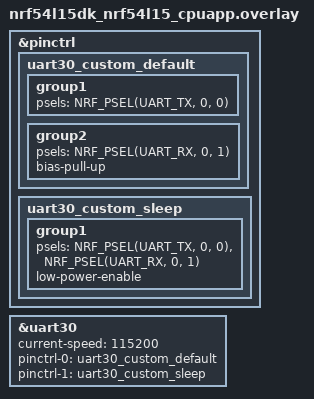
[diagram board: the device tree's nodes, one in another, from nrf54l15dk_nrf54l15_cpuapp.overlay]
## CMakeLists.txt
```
#
# Copyright (c) 2019 Nordic Semiconductor ASA
#
# SPDX-License-Identifier: LicenseRef-Nordic-5-Clause
#
cmake_minimum_required(VERSION 3.20.0)

find_package(Zephyr REQUIRED HINTS $ENV{ZEPHYR_BASE})
project(mesh_shell)

include_directories(${ZEPHYR_NRF_MODULE_DIR}/samples/bluetooth/mesh/common)

# NORDIC SDK APP START
target_sources(app PRIVATE
  src/main.c
  src/model_handler.c
  src/uart_cmd.c
  src/provisioning.c
  src/init.c
  src/gtw_shell.c
  src/keyrefresh.c
)
target_include_directories(app PRIVATE
  include
  ${ZEPHYR_NRF_MODULE_DIR}/samples/bluetooth/mesh/common
)

# Preinitialization related to DFU over SMP
target_sources_ifdef(CONFIG_MCUMGR_TRANSPORT_BT app PRIVATE
  ${ZEPHYR_NRF_MODULE_DIR}/samples/bluetooth/mesh/common/smp_bt.c
)

# NORDIC SDK APP END
```

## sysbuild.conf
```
#
# Copyright (c) 2020 Nordic Semiconductor ASA
#
# SPDX-License-Identifier: LicenseRef-Nordic-5-Clause
#
# Sysbuild configuration
# TFM UART configuration is passed via tfm_EXTRA_CONF_FILE or tfm image config
```

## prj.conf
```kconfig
#
# Copyright (c) 2020 Nordic Semiconductor ASA
#
# SPDX-License-Identifier: LicenseRef-Nordic-5-Clause
#

CONFIG_TEST=y
CONFIG_TEST_LOGGING_DEFAULTS=n
#CONFIG_INIT_STACKS=y
CONFIG_MAIN_STACK_SIZE=4096
CONFIG_ISR_STACK_SIZE=2048
CONFIG_SYSTEM_WORKQUEUE_STACK_SIZE=8192
CONFIG_SHELL_STACK_SIZE=4096

CONFIG_SHELL=y
CONFIG_SHELL_CMD_BUFF_SIZE=256
# CONFIG_SHELL_BACKEND_SERIAL=y
# CONFIG_SHELL_BACKEND_SERIAL_API_ASYNC=n
# CONFIG_SHELL_BACKEND_SERIAL_API_INTERRUPT_DRIVEN=y
CONFIG_UART_INTERRUPT_DRIVEN=y


# Dummy backend to capture shell output
CONFIG_SHELL_BACKEND_DUMMY=y
CONFIG_SHELL_BACKEND_DUMMY_BUF_SIZE=4096

# Use RTT for logging and shell
CONFIG_USE_SEGGER_RTT=y
CONFIG_RTT_CONSOLE=y
CONFIG_UART_CONSOLE=n
CONFIG_SHELL_BACKEND_SERIAL=n
CONFIG_SHELL_BACKEND_RTT=y
CONFIG_LOG_BACKEND_RTT=y
CONFIG_LOG_BACKEND_UART=n
# Use different RTT channels for shell and log
CONFIG_SHELL_BACKEND_RTT_BUFFER=0
CONFIG_LOG_BACKEND_RTT_BUFFER=1

CONFIG_BT_SETTINGS=y
CONFIG_FLASH=y
CONFIG_FLASH_MAP=y
CONFIG_SETTINGS=y
# CONFIG_SECURE_STORAGE=y

CONFIG_BT=y
CONFIG_BT_OBSERVER=y
CONFIG_BT_PERIPHERAL=y
CONFIG_BT_DEVICE_NAME="Zephyr Mesh"
CONFIG_BT_GATT_CACHING=n

CONFIG_BT_CTLR_LE_ENC=n
CONFIG_BT_CTLR_LE_PING=n
CONFIG_BT_DATA_LEN_UPDATE=n
CONFIG_BT_PHY_UPDATE=n
CONFIG_BT_CTLR_MIN_USED_CHAN=n
CONFIG_BT_CTLR_PRIVACY=n
CONFIG_BT_CTLR_DTM_HCI=n
CONFIG_BT_CTLR_EXT_SCAN_FP=n
CONFIG_BT_DATA_LEN_UPDATE=n
CONFIG_BT_CTLR_PER_INIT_FEAT_XCHG=n
#CONFIG_BT_CTLR_ADVANCED_FEATURES=y
CONFIG_BT_CTLR_FILTER_ACCEPT_LIST=n

CONFIG_BT_L2CAP_TX_BUF_COUNT=4


CONFIG_BT_RX_STACK_SIZE=4096

CONFIG_BT_MESH=y
CONFIG_BT_MESH_SHELL=y
CONFIG_BT_MESH_SHELL_HEALTH_SRV_INSTANCE=y
CONFIG_BT_MESH_SHELL_PROV_CTX_INSTANCE=y
CONFIG_BT_MESH_RELAY=y
CONFIG_BT_MESH_LOW_POWER=n
CONFIG_BT_MESH_LPN_AUTO=n
CONFIG_BT_MESH_FRIEND=y
CONFIG_BT_MESH_FRIEND_QUEUE_SIZE=16
CONFIG_BT_MESH_ADV_BUF_COUNT=9

CONFIG_BT_MESH_ADV_STACK_SIZE=4096
CONFIG_BT_MESH_CFG_CLI=y
CONFIG_BT_MESH_CFG_CLI_TIMEOUT=6000
CONFIG_BT_MESH_HEALTH_CLI=y
CONFIG_BT_MESH_TX_SEG_MSG_COUNT=2
CONFIG_BT_MESH_RX_SEG_MSG_COUNT=2
CONFIG_BT_MESH_RX_SEG_MAX=32
CONFIG_BT_MESH_TX_SEG_MAX=32
CONFIG_BT_MESH_CRPL=128

CONFIG_BT_MESH_PB_GATT=y
CONFIG_BT_MESH_PB_ADV=y
CONFIG_BT_MESH_GATT_PROXY=y
CONFIG_BT_MESH_NODE_ID_TIMEOUT=10

# The gateway must be a member of every subnet it provisions devices onto (to
# configure and drive those nodes), so it needs more than the default of 1
# subnet. Capped below CDB_SUBNET_COUNT by RAM; prov_ensure_subnet reports a
# clean error if a provisioning would exceed this.
CONFIG_BT_MESH_SUBNET_COUNT=10
CONFIG_BT_MESH_APP_KEY_COUNT=20
# PTS requires more key slots when using Opcodes Aggregator.
# First one is implicitly taken by Device Key.
CONFIG_BT_MESH_MODEL_KEY_COUNT=10
CONFIG_BT_MESH_MODEL_GROUP_COUNT=2
CONFIG_BT_MESH_LABEL_COUNT=1

CONFIG_LOG=y
CONFIG_LOG_BUFFER_SIZE=4096
CONFIG_LOG_PROCESS_THREAD_SLEEP_MS=100
CONFIG_LOG_MODE_DEFERRED=y

CONFIG_BT_MESH_IV_UPDATE_TEST=y
# INF (not DBG): verbose mesh debug logging floods deferred RTT logging during
# heavy mesh traffic, adding CPU/timing pressure that can push HCI commands past
# their timeout. INF keeps useful info logs without the per-PDU debug spam.
CONFIG_BT_MESH_LOG_LEVEL_INF=y
CONFIG_BT_MESH_CDB=y
CONFIG_BT_MESH_CDB_SUBNET_COUNT=10
CONFIG_BT_MESH_CDB_APP_KEY_COUNT=15
CONFIG_BT_MESH_CDB_NODE_COUNT=128
CONFIG_BT_MESH_PROVISIONER=y

#Added includes
CONFIG_DK_LIBRARY=y
CONFIG_BT_MESH_ONOFF_SRV=y
CONFIG_BT_MESH_ONOFF_CLI=y
CONFIG_BT_MESH_LIGHTNESS_CLI=y
CONFIG_BT_MESH_SCENE_CLI=y
CONFIG_BT_MESH_SENSOR_CLI=y
CONFIG_BT_MESH_RPR_CLI=y
CONFIG_BT_MESH_SHELL_RPR_CLI=n

# CONFIG_TFM_ITS_NUM_ASSETS_OVERRIDE=y
# CONFIG_TFM_ITS_NUM_ASSETS=50
# CONFIG_PM_PARTITION_SIZE_TFM_INTERNAL_TRUSTED_STORAGE=0x8000

CONFIG_MBEDTLS_HEAP_SIZE=16384
CONFIG_MBEDTLS_PSA_KEY_SLOT_COUNT=64

# UART30 for board-to-board command reception (see board overlay)
CONFIG_SERIAL=y
CONFIG_UART_30_INTERRUPT_DRIVEN=y
CONFIG_BT_MESH_CDB_KEY_SYNC=y

CONFIG_NRF_PLATFORM_LUMOS=n
```

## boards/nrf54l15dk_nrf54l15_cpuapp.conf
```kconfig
#
# Copyright (c) 2024 Nordic Semiconductor ASA
#
# SPDX-License-Identifier: LicenseRef-Nordic-5-Clause
#
# nRF54L15 uses ZMS (RRAM), not NVS. Required for mesh trusted storage backend.

CONFIG_NVS=n
CONFIG_NVS_LOOKUP_CACHE=n
CONFIG_SETTINGS_NVS_NAME_CACHE=n
CONFIG_ZMS=y
CONFIG_SETTINGS_ZMS_CUSTOM_SECTOR_COUNT=y
CONFIG_SETTINGS_ZMS_SECTOR_COUNT=8
CONFIG_ZMS_LOOKUP_CACHE=y
CONFIG_ZMS_LOOKUP_CACHE_SIZE=512
CONFIG_ZMS_LOOKUP_CACHE_FOR_SETTINGS=y
```

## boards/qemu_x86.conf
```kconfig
# Copyright (c) 2026 Nordic Semiconductor ASA
# SPDX-License-Identifier: LicenseRef-Nordic-5-Clause

# nrf_security only supports Cortex-M via PSA crypto libraries.
# Enforcing usage of built-in Mbed TLS for native simulator.
CONFIG_NRF_SECURITY=n
CONFIG_MBEDTLS_ENABLE_HEAP=n
CONFIG_TRUSTED_STORAGE=n
CONFIG_SECURE_STORAGE=y
```

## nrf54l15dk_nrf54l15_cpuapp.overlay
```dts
/*
 * Copyright (c) 2026 Nordic Semiconductor ASA
 *
 * SPDX-License-Identifier: LicenseRef-Nordic-5-Clause
 */

/*
 * UART30 overlay for board-to-board command communication with nRF9151 gateway.
 * Console uses RTT in this application; UART20 is unused.
 * Hardware flow control (RTS/CTS) disabled for simple 2-wire UART.
 */

&pinctrl {
	uart30_custom_default: uart30_custom_default {
		group1 {
			psels = <NRF_PSEL(UART_TX, 0, 0)>;
		};
		group2 {
			psels = <NRF_PSEL(UART_RX, 0, 1)>;
			bias-pull-up;
		};
	};

	uart30_custom_sleep: uart30_custom_sleep {
		group1 {
			psels = <NRF_PSEL(UART_TX, 0, 0)>,
				<NRF_PSEL(UART_RX, 0, 1)>;
			low-power-enable;
		};
	};
};

&uart30 {
	status = "okay";
	current-speed = <115200>;
	pinctrl-0 = <&uart30_custom_default>;
	pinctrl-1 = <&uart30_custom_sleep>;
	pinctrl-names = "default", "sleep";
};
```

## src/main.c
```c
/*
 * Copyright (c) 2017 Intel Corporation
 * Copyright (c) 2026 Nordic Semiconductor ASA
 *
 * SPDX-License-Identifier: Apache-2.0
 */

#include <zephyr/sys/printk.h>
#include <zephyr/console/console.h>
#include <zephyr/kernel.h>
#include <zephyr/bluetooth/bluetooth.h>
#include <bluetooth/mesh/models.h>
#include <bluetooth/mesh/dk_prov.h>
#include <dk_buttons_and_leds.h>
#include <zephyr/shell/shell.h>
#include <zephyr/shell/shell_uart.h>
#include <zephyr/shell/shell_dummy.h>
#include <zephyr/bluetooth/mesh/shell.h>
#include "model_handler.h"
#include "init.h"
#include "uart_cmd.h"
#include "smp_bt.h"
#include "provisioning.h"

/*ADDED INCLUDES*/
#include <zephyr/settings/settings.h>
#include <zephyr/drivers/uart.h>
#include <zephyr/logging/log_backend.h>
#include <zephyr/logging/log_output.h>
#include <zephyr/logging/log_ctrl.h>
#include <zephyr/sys/ring_buffer.h>
#include <string.h>
#include <stdio.h>

#if defined(CONFIG_SETTINGS)
#include <zephyr/settings/settings.h>
#endif



int main(void)
{
	int err;

	printk("Initializing...\n");
	err = bt_enable(bt_ready);
	if (err && err != -EALREADY) {
		printk("Bluetooth init failed (err %d)\n", err);
	}
	err = uart_cmd_init();
	if (err) {
		printk("UART command init failed (err %d)\n", err);
	}
	provisioning_init();
	printk("Press the <Tab> button for supported commands.\n");
	printk("Before any Mesh commands you must run \"mesh init\"\n");
	printk("Ready to receive commands via UART...\n");
	while (1) {
		k_sleep(K_FOREVER);
	}
	return 0;
}
```

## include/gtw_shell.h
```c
/*
 * Copyright (c) 2026 Nordic Semiconductor ASA
 *
 * SPDX-License-Identifier: LicenseRef-Nordic-5-Clause
 */

#ifndef GTW_SHELL_H
#define GTW_SHELL_H

#define STATUS_GROUP_ADDR 0xC000

bool queue_shell_cmd(const char *cmd);

#endif /* GTW_SHELL_H */
```

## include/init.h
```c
/*
 * Copyright (c) 2019 Nordic Semiconductor ASA
 *
 * SPDX-License-Identifier: LicenseRef-Nordic-5-Clause
 */

/**
 * @file
 * @brief Model handler
 */

#ifndef INIT_H
#define INIT_H

#include <zephyr/drivers/uart.h>
#include <zephyr/bluetooth/bluetooth.h>

#ifdef __cplusplus
extern "C" {
#endif

int uart_cmd_init(void);
void bt_ready(int err);


#ifdef __cplusplus
}
#endif

#endif /* INIT_H__ */
```

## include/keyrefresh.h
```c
/*
 * Copyright (c) 2026 Nordic Semiconductor ASA
 *
 * SPDX-License-Identifier: LicenseRef-Nordic-5-Clause
 */

#ifndef KEYREFRESH_H
#define KEYREFRESH_H

#include <stddef.h>
#include <stdint.h>

#ifdef __cplusplus
extern "C" {
#endif

/* One subnet to refresh and the remote nodes that hold it. The gateway is
 * always refreshed too, so it is not listed.
 */
struct kr_subnet {
	uint16_t net_idx;
	const uint16_t *addrs;
	size_t addr_count;
};

/* Run the Bluetooth Mesh Key Refresh on the selected
 * NetKeys and AppKeys
 */
void key_refresh_run(const struct kr_subnet *subnets, size_t subnet_count,
		     const uint16_t *app_idxs, size_t app_count,
		     uint16_t evict_addr);

#ifdef __cplusplus
}
#endif

#endif /* KEYREFRESH_H */
```

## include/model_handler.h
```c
/*
 * Copyright (c) 2026 Nordic Semiconductor ASA
 *
 * SPDX-License-Identifier: LicenseRef-Nordic-5-Clause
 */

/**
 * @file
 * @brief Model handler
 */

#ifndef MODEL_HANDLER_H__
#define MODEL_HANDLER_H__

#include <stdbool.h>
#include <stdint.h>
#include <zephyr/bluetooth/mesh.h>

#ifdef __cplusplus
extern "C" {
#endif

const struct bt_mesh_comp *model_handler_init(void);
int model_handler_onoff_set(uint16_t net_idx, uint16_t app_idx, uint16_t dst_addr, bool on_off);

/* Set absolute brightness (0-100%) on a Light Lightness Server (light_ctrl fixture). */
int model_handler_lightness_set(uint16_t net_idx, uint16_t app_idx, uint16_t dst_addr,
				uint8_t percent);

/* Recall/store a scene on a Scene Server. */
int model_handler_scene_recall(uint16_t net_idx, uint16_t app_idx, uint16_t dst_addr,
			       uint16_t scene);
int model_handler_scene_store(uint16_t net_idx, uint16_t app_idx, uint16_t dst_addr,
			      uint16_t scene);

/* Read bt_mesh_sensor_precise_tot_dev_energy_use
 */
int model_handler_sensor_get(uint16_t net_idx, uint16_t app_idx, uint16_t dst_addr);

#if defined(CONFIG_BT_MESH_RPR_CLI)
/* Remote Provisioning Client model instance */
struct bt_mesh_rpr_cli *model_handler_rpr_cli(void);
#endif

#ifdef __cplusplus
}
#endif

#endif /* MODEL_HANDLER_H__ */
```

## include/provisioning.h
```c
/*
 * Copyright (c) 2026 Nordic Semiconductor ASA
 *
 * SPDX-License-Identifier: LicenseRef-Nordic-5-Clause
 */

#ifndef PROVISIONING_H
#define PROVISIONING_H

#include <stdbool.h>
#include <stdint.h>

#ifdef __cplusplus
extern "C" {
#endif

/* Control/status group the gateway subscribes its own client models to, and the
 * group fixtures publish their status to, so the cloud sees state changes from any
 * source. Shared by the local-model setup in uart_cmd.c and the remote-node
 * auto-configuration here.
 */
#define STATUS_GROUP_ADDR 0xC000

/* One-time provisioning subsystem setup */
void provisioning_init(void);

/* Ensure subnet `net_idx` exists in the CDB and is added to the gateway's own
 * node
 */
int prov_ensure_subnet(uint16_t net_idx, const char *netkey_hex);

/* Add subnet to an already-provisioned node
 */
int prov_node_add_subnet(uint16_t net_idx, uint16_t addr, uint16_t add_net_idx);

/* Remove subnet from a node */
int prov_node_del_subnet(uint16_t net_idx, uint16_t addr, uint16_t del_net_idx);

/* Remove one AppKey from a node */
int prov_node_del_appkey(uint16_t net_idx, uint16_t addr, uint16_t app_idx);

/* Remove a group address from a node: unsubscribe its models from the group and
 * clear any publication aimed at it.
 */
int prov_node_del_group(uint16_t net_idx, uint16_t addr, uint16_t group);

/* Toggle combined scanning: local unprovisioned beacons + remote RPR relays. */
void prov_scan_toggle(void);

/* Toggle REMOTE-ONLY scanning: RPR relays only, local beacons stay off. */
void prov_scan_rpr_toggle(void);

/* Enable/disable auto-provisioning of newly discovered unprovisioned devices. */
void prov_auto_set(bool enable);

/* net_idx/app_idx/group to use for provisioning. */
extern uint16_t cur_net_idx;
extern uint16_t cur_app_idx;
extern uint16_t cur_group;

/* Provision a discovered device (by UUID). Tunnels through the discovering RPR
 * relay if the UUID was seen remotely, otherwise provisions locally over PB-ADV.
 */
void prov_provision(const char *uuid);

/* Register a node address as a known RPR Server relay (dedup-insert). */
void prov_rpr_server_add(uint16_t addr);

/* Report the registered RPR Server relays to the cloud. */
void prov_rpr_server_list(void);

/* Read a freshly provisioned node's composition data and queue configuration
 * commands for the models the gateway recognizes.
 */
void configure_and_report(uint16_t addr, uint16_t net_idx, uint16_t app_idx,
			      uint16_t group);

#ifdef __cplusplus
}
#endif

#endif /* PROVISIONING_H */
```

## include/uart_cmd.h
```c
/*
 * Copyright (c) 2026 Nordic Semiconductor ASA
 *
 * SPDX-License-Identifier: LicenseRef-Nordic-5-Clause
 */

#ifndef UART_CMD_H
#define UART_CMD_H

#include <zephyr/drivers/uart.h>
#include <zephyr/kernel.h>

#ifdef __cplusplus
extern "C" {
#endif

void uart30_send(const char *data, const char *subject);


#ifdef __cplusplus
}
#endif

#endif /* UART_CMD_H */
```

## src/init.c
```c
/*
 * Copyright (c) 2026 Nordic Semiconductor ASA
 *
 * SPDX-License-Identifier: LicenseRef-Nordic-5-Clause
 */

/*UART INIT*/
#include "init.h"
#include <zephyr/drivers/uart.h>
#include <zephyr/bluetooth/mesh/shell.h>
#include <zephyr/bluetooth/bluetooth.h>
#include <zephyr/settings/settings.h>
#include <zephyr/sys/printk.h>
#include "model_handler.h"

void bt_ready(int err)
{
	if (err && err != -EALREADY) {
		printk("Bluetooth init failed (err %d)\n", err);
		return;
	}
	printk("Bluetooth initialized\n");
	int mesh_err = bt_mesh_init(&bt_mesh_shell_prov, model_handler_init());

	if (mesh_err) {
		printk("Initializing mesh failed (err %d)\n", mesh_err);
		return;
	}
	if (IS_ENABLED(CONFIG_SETTINGS)) {
		settings_load();
	}
	if (bt_mesh_is_provisioned()) {
		printk("Mesh network restored from flash\n");
	} else {
		printk("Use \"prov pb-adv on\" or \"prov pb-gatt on\" to enable advertising\n");
	}
}
```

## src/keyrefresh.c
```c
/*
 * Copyright (c) 2026 Nordic Semiconductor ASA
 *
 * SPDX-License-Identifier: LicenseRef-Nordic-5-Clause
 */

#include "keyrefresh.h"
#include "uart_cmd.h"   /* uart30_send */

#include <stdbool.h>
#include <stdint.h>
#include <stddef.h>
#include <stdio.h>

#include <zephyr/kernel.h>
#include <zephyr/sys/printk.h>
#include <zephyr/sys/util.h>

#include <zephyr/bluetooth/mesh.h>
#include <zephyr/bluetooth/mesh/cdb.h>
#include <zephyr/bluetooth/mesh/cfg_cli.h>
#include <zephyr/bluetooth/crypto.h>

/* bt_mesh_primary_addr() (the gateway's own primary unicast) */
uint16_t bt_mesh_primary_addr(void);

/* Bluetooth Mesh Key Refresh phase/transition values */
#define KR_PHASE_NORMAL   0x00
#define KR_PHASE_1	0x01
#define KR_PHASE_2	0x02
#define KR_TRANS_PHASE_2  0x02
#define KR_TRANS_PHASE_3  0x03

/* All provisioned nodes plus the local gateway (not stored in the CDB). */
#define KR_MAX_TARGETS    (CONFIG_BT_MESH_CDB_NODE_COUNT + 1)

/* Scratch buffer for the target list. Only ever touched by the single
 * serialized worker that runs key_refresh_run().
 */
static uint16_t kr_targets[KR_MAX_TARGETS];

/* Is app_idx one of the `count` selected AppKeys? */
static bool kr_app_selected(uint16_t app_idx, const uint16_t *sel, size_t count)
{
	for (size_t i = 0; i < count; i++) {
		if (sel[i] == app_idx) {
			return true;
		}
	}
	return false;
}

/* Runs the full three-phase Key Refresh for one subnet, rolling its NetKey and */
/* every selected AppKey (`sel`/`sel_count`) that is bound to this subnet. */
static void key_refresh_subnet(const struct kr_subnet *target,
				   const uint16_t *sel, size_t sel_count,
				   uint16_t evict_addr, bool del_evicted)
{
	uint16_t refresh_net_idx = target->net_idx;
	struct bt_mesh_cdb_subnet *sub = bt_mesh_cdb_subnet_get(refresh_net_idx);
	uint16_t local_addr = bt_mesh_primary_addr();
	uint8_t new_key[16];
	/* One fresh value per CDB AppKey slot (only meaningful where ak_done[] is */
	/* set), indexed by the slot's position in bt_mesh_cdb.app_keys[]. */
	uint8_t new_app_keys[ARRAY_SIZE(bt_mesh_cdb.app_keys)][16];
	bool ak_done[ARRAY_SIZE(bt_mesh_cdb.app_keys)] = { 0 };
	size_t ak_count = 0;
	char resp[192];
	size_t n;
	int p1_fail = 0, p2_fail = 0, p3_fail = 0, ak_fail = 0;

	/* All key_refresh_run failures report under the "KeyRefresh" subject (not */
	/* "Error") so the website — which set its status to "running" the moment the */
	/* command was dispatched — routes them to its key-refresh handler and clears */
	/* that pending state instead of leaving the badge stuck. */
	if (!sub) {
		snprintf(resp, sizeof(resp), "key refresh: no subnet 0x%03x in database",
			refresh_net_idx);
		printk("%s\n", resp);
		uart30_send(resp, "KeyRefresh");
		return;
	}
	if (sub->kr_phase != KR_PHASE_NORMAL) {
		snprintf(resp, sizeof(resp),
			"key refresh: subnet 0x%03x already refreshing (phase 0x%02x)",
			refresh_net_idx, sub->kr_phase);
		printk("%s\n", resp);
		uart30_send(resp, "KeyRefresh");
		return;
	}
	/* Evicting the gateway's own node would leave every remote on the new key */
	/* while the gateway keeps the old one, partitioning it from the network it */
	/* provisions. Never allow it. */
	if (evict_addr && evict_addr == local_addr) {
		snprintf(resp, sizeof(resp),
			"key refresh: refusing to evict gateway 0x%04x", local_addr);
		printk("%s\n", resp);
		uart30_send(resp, "KeyRefresh");
		return;
	}

	/* One fresh random NetKey shared by every node. The same value MUST reach */
	/* all nodes, so we generate it once here rather than letting each config */
	/* command mint its own (the shell would fall back to the default key). */
	if (bt_rand(new_key, sizeof(new_key))) {
		uart30_send("key refresh: RNG failed", "KeyRefresh");
		return;
	}

	/* Target list: the nodes the caller says hold this subnet (the gateway */
	/* does not track which subnets each node holds), then the local gateway, */
	/* which holds every subnet and goes last so it keeps the old key until */
	/* every remote has switched. */
	n = 0;
	for (size_t i = 0; i < target->addr_count && n < KR_MAX_TARGETS - 1; i++) {
		uint16_t addr = target->addrs[i];

		if (addr == evict_addr || addr == local_addr) {
			continue;
		}
		if (!bt_mesh_cdb_node_get(addr)) {
			printk("  0x%04x not in database, skipping\n", addr);
			continue;
		}
		kr_targets[n++] = addr;
	}
	if (local_addr) {
		kr_targets[n++] = local_addr;
	}
	if (n == 0) {
		uart30_send("key refresh: no target nodes", "KeyRefresh");
		return;
	}

	printk("Key refresh on subnet 0x%03x: %u node(s)%s\n", refresh_net_idx,
	   (unsigned int)n, evict_addr ? " (evicting one)" : "");
	snprintf(resp, sizeof(resp), "started subnet 0x%03x nodes=%u evict=0x%04x",
		 refresh_net_idx, (unsigned int)n, evict_addr);
	uart30_send(resp, "KeyRefresh");

	/* ---- Phase 1: distribute the new key (§3.11.4.1) ---- */
	/* Record the new key in the database as the "new" key (index 1) first, then */
	/* push it to each node. A NetKey Update moves a node from Normal to Phase 1; */
	/* it then keeps TX on the old key and RX on both keys. */
	bt_mesh_cdb_subnet_key_import(sub, 1, new_key);
	sub->kr_phase = KR_PHASE_1;
	bt_mesh_cdb_subnet_store(sub);

	for (size_t i = 0; i < n; i++) {
		uint8_t status = 0;
		int err = bt_mesh_cfg_cli_net_key_update(refresh_net_idx, kr_targets[i],
							refresh_net_idx, new_key, &status);
		if (err || status) {
			p1_fail++;
			printk("  P1 net-key-update 0x%04x FAILED (err %d, status 0x%02x)\n",
			kr_targets[i], err, status);
		}
	}

	/* The selected AppKeys on this subnet, refreshed while still in Phase 1. */
	for (size_t ak = 0; ak < ARRAY_SIZE(bt_mesh_cdb.app_keys); ak++) {
		struct bt_mesh_cdb_app_key *key = &bt_mesh_cdb.app_keys[ak];

		/* Only refresh selected AppKeys bound to this NetKey. */
		if (key->net_idx != refresh_net_idx ||
			!kr_app_selected(key->app_idx, sel, sel_count)) {
			continue;
		}
		if (bt_rand(new_app_keys[ak], sizeof(new_app_keys[ak]))) {
			printk("  AppKey 0x%04x: RNG failed, skipping\n", key->app_idx);
			continue;
		}

		bt_mesh_cdb_app_key_import(key, 1, new_app_keys[ak]);
		ak_done[ak] = true;
		ak_count++;

		for (size_t i = 0; i < n; i++) {
			uint8_t status = 0;
			int err = bt_mesh_cfg_cli_app_key_update(refresh_net_idx, kr_targets[i],
								refresh_net_idx, key->app_idx,
								new_app_keys[ak], &status);
			if (err) {
				ak_fail++;
				printk("  P1 app-key-update 0x%04x appidx=0x%04x FAILED (err %d)\n",
					kr_targets[i], key->app_idx, err);
			} else if (status) {
				printk(
			"  P1 app-key-update 0x%04x appidx=0x%04x not applicable (status 0x%02x)\n",
					kr_targets[i], key->app_idx, status);
			}
		}
	}

	/* ---- Phase 2: switch every node's TX to the new key (§3.11.4.2) ---- */
	for (size_t i = 0; i < n; i++) {
		uint8_t status = 0, phase = 0;
		int err = bt_mesh_cfg_cli_krp_set(refresh_net_idx, kr_targets[i],
						refresh_net_idx, KR_TRANS_PHASE_2,
						&status, &phase);
		if (err || status || phase != KR_PHASE_2) {
			p2_fail++;
			printk("  P2 krp-set 0x%04x FAILED (err %d, status 0x%02x, phase 0x%02x)\n",
				kr_targets[i], err, status, phase);
		}
	}
	sub->kr_phase = KR_PHASE_2;
	bt_mesh_cdb_subnet_store(sub);

	/* ---- Phase 3: revoke the old key (§3.11.4.3) ---- */
	/* Iterating in build order revokes the local gateway last, so it keeps a */
	/* working old key until every remote has switched. Each node settles back */
	/* to Normal (0x00) once the old key is revoked. */
	for (size_t i = 0; i < n; i++) {
		uint8_t status = 0, phase = 0;
		int err = bt_mesh_cfg_cli_krp_set(refresh_net_idx, kr_targets[i],
						refresh_net_idx, KR_TRANS_PHASE_3,
						&status, &phase);
		if (err || status || phase != KR_PHASE_NORMAL) {
			p3_fail++;
			printk("  P3 krp-set 0x%04x FAILED (err %d, status 0x%02x, phase 0x%02x)\n",
				kr_targets[i], err, status, phase);
		}
	}

	/* The new key is now the sole key on the network; mirror that in the CDB. */
	bt_mesh_cdb_subnet_key_import(sub, 0, new_key);
	sub->kr_phase = KR_PHASE_NORMAL;
	bt_mesh_cdb_subnet_store(sub);

	/* Same promotion for every AppKey that was refreshed above. */
	for (size_t ak = 0; ak < ARRAY_SIZE(bt_mesh_cdb.app_keys); ak++) {
		if (!ak_done[ak]) {
			continue;
		}
		struct bt_mesh_cdb_app_key *key = &bt_mesh_cdb.app_keys[ak];

		bt_mesh_cdb_app_key_import(key, 0, new_app_keys[ak]);
		bt_mesh_cdb_app_key_store(key);
	}

	/* An evicted node never received the new key and is now off the network, so */
	/* drop it from the database as well. Skipped when several subnets are */
	/* refreshed: key_refresh_run removes the node once, after the last subnet. */
	if (del_evicted && evict_addr) {
		struct bt_mesh_cdb_node *gone = bt_mesh_cdb_node_get(evict_addr);

		if (gone) {
			bt_mesh_cdb_node_del(gone, true);
			printk("Evicted node 0x%04x removed from database\n", evict_addr);
		}
	}

	snprintf(resp, sizeof(resp),
		 "complete subnet 0x%03x nodes=%u appkeys=%u fails p1=%d p2=%d p3=%d ak=%d%s",
		 refresh_net_idx, (unsigned int)n, (unsigned int)ak_count,
		 p1_fail, p2_fail, p3_fail, ak_fail,
		 evict_addr ? " evicted" : "");
	printk("Key refresh %s\n", resp);
	uart30_send(resp, "KeyRefresh");
}

/* Refresh the selected subnets' NetKeys (`subnets`/`subnet_count`), each across
 * the nodes listed with it, optionally rolling the selected AppKeys
 * (`app_idxs`/`app_count`) alongside their own subnet's NetKey.
 */
void key_refresh_run(const struct kr_subnet *subnets, size_t subnet_count,
		     const uint16_t *app_idxs, size_t app_count,
		     uint16_t evict_addr)
{
	char resp[96];

	if (subnet_count == 0) {
		uart30_send("key refresh: no subnet selected", "KeyRefresh");
		return;
	}

	/* An AppKey is only rolled with its own subnet, whose node list must be */
	/* in the command - flag any whose subnet was not selected. */
	for (size_t i = 0; i < app_count; i++) {
		struct bt_mesh_cdb_app_key *key = bt_mesh_cdb_app_key_get(app_idxs[i]);
		bool selected = false;

		if (!key) {
			snprintf(resp, sizeof(resp),
				"key refresh: app_idx 0x%03x not in database", app_idxs[i]);
			printk("%s\n", resp);
			uart30_send(resp, "KeyRefresh");
			continue;
		}
		for (size_t j = 0; j < subnet_count; j++) {
			if (subnets[j].net_idx == key->net_idx) {
				selected = true;
				break;
			}
		}
		if (!selected) {
			snprintf(resp, sizeof(resp),
				"key refresh: app_idx 0x%03x skipped, its subnet 0x%03x not selected",
				app_idxs[i], key->net_idx);
			printk("%s\n", resp);
			uart30_send(resp, "KeyRefresh");
		}
	}

	/* Refresh each subnet once, passing the full AppKey selection; the subnet
	 * routine rolls its NetKey plus the selected AppKeys bound to it.
	 * Defer the evicted-node removal to after the last subnet.
	 */
	for (size_t j = 0; j < subnet_count; j++) {
		key_refresh_subnet(&subnets[j], app_idxs, app_count, evict_addr,
				/* del_evicted = */ false);
	}

	/* Each subnet refused to evict the gateway itself (it must stay on the new */
	/* key), so never drop the local node here either - only a genuine remote. */
	if (evict_addr && evict_addr != bt_mesh_primary_addr()) {
		struct bt_mesh_cdb_node *gone = bt_mesh_cdb_node_get(evict_addr);

		if (gone) {
			bt_mesh_cdb_node_del(gone, true);
			printk("Evicted node 0x%04x removed from database\n", evict_addr);
		}
	}
}
```

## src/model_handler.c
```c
/*
 * Copyright (c) 2026 Nordic Semiconductor ASA
 *
 * SPDX-License-Identifier: LicenseRef-Nordic-5-Clause
 */

#include <zephyr/bluetooth/bluetooth.h>
#include <bluetooth/mesh/models.h>
#include <bluetooth/mesh/gen_onoff_cli.h>
#include <errno.h>
#include <stdio.h>
#include <zephyr/sys/printk.h>
#include "uart_cmd.h"

/*ADDED INCLUDES*/
#include <zephyr/shell/shell.h>
#include <zephyr/bluetooth/mesh/shell.h>

static struct bt_mesh_cfg_cli cfg_cli;

#if defined(CONFIG_BT_MESH_RPR_CLI)
/* Remote Provisioning Client instance */
static struct bt_mesh_rpr_cli rpr_cli;

struct bt_mesh_rpr_cli *model_handler_rpr_cli(void)
{
	return &rpr_cli;
}
#endif

/* callback for receiving on/off status messages from the mesh network, sends status to cloud */
static void OnOff_status_cb(struct bt_mesh_onoff_cli *cli,
			    struct bt_mesh_msg_ctx *ctx,
			    const struct bt_mesh_onoff_status *status)
{
	(void)cli;

	if (!ctx || !status) {
		printk("OnOff status callback received invalid data\n");
		return;
	}

	printk("OnOff status from 0x%04x: status=%u",
	       ctx->addr,
	       status->present_on_off ? 1U : 0U);

	if (status->remaining_time >= 0) {
		printk(", target=%u, remaining=%ld ms",
		       status->target_on_off ? 1U : 0U,
		       (long)status->remaining_time);
	}

	printk("\n");

	char status_msg[96];

	snprintf(status_msg, sizeof(status_msg),
		 "src=0x%04x status=%s",
		 ctx->addr,
		 status->present_on_off ? "ON" : "OFF");
	uart30_send(status_msg, "OnOff_status");
}

static struct bt_mesh_onoff_cli onoff_cli = BT_MESH_ONOFF_CLI_INIT(OnOff_status_cb);

/* callback for Light Lightness status, forwards the brightness level to the cloud */
static void lightness_status_cb(struct bt_mesh_lightness_cli *cli,
				struct bt_mesh_msg_ctx *ctx,
				const struct bt_mesh_lightness_status *status)
{
	(void)cli;

	if (!ctx || !status) {
		return;
	}

	printk("Lightness status from 0x%04x: lvl=%u\n", ctx->addr, status->current);

	char msg[96];

	snprintf(msg, sizeof(msg), "src=0x%04x lvl=%u", ctx->addr, status->current);
	/* Subject must be <=15 chars: the nRF9151 forwarder parses the appId with
	 * sscanf("%15s") into a 16-byte buffer, so "Lightness_status" (16) would be
	 * truncated to "Lightness_statu" and never match on the cloud side.
	 */
	uart30_send(msg, "Light_status");
}

static const struct bt_mesh_lightness_cli_handlers lightness_cli_handlers = {
	.light_status = lightness_status_cb,
};

/* Light Lightness client, used by the gateway to set absolute brightness on fixtures */
static struct bt_mesh_lightness_cli lightness_cli =
	BT_MESH_LIGHTNESS_CLI_INIT(&lightness_cli_handlers);

/* callback for Scene status, forwards the current scene to the cloud */
static void scene_status_cb(struct bt_mesh_scene_cli *cli,
			    struct bt_mesh_msg_ctx *ctx,
			    const struct bt_mesh_scene_state *state)
{
	(void)cli;

	if (!ctx || !state) {
		return;
	}

	printk("Scene status from 0x%04x: current=%u\n", ctx->addr, state->current);

	char msg[96];

	snprintf(msg, sizeof(msg), "src=0x%04x scene=%u", ctx->addr, state->current);
	uart30_send(msg, "Scene_status");
}

/* Scene client, used by the gateway to store/recall scenes on fixtures */
static struct bt_mesh_scene_cli scene_cli = {
	.status = scene_status_cb,
};

/* callback for Sensor Status: decode the Precise Total Device Energy Use value
 * and forward it to the cloud. The Sensor Client already decodes the on-air
 * wire format into a bt_mesh_sensor_value; we convert that to a number using
 * the property's format (energy32: unit kWh, resolution 0.001 kWh).
 */
static void sensor_data_cb(struct bt_mesh_sensor_cli *cli,
			   struct bt_mesh_msg_ctx *ctx,
			   const struct bt_mesh_sensor_type *sensor,
			   const struct bt_mesh_sensor_value *value)
{
	(void)cli;

	if (!ctx || !sensor || !value) {
		return;
	}

	/* The gateway only queries the energy-use sensor; ignore anything else */
	if (sensor->id != BT_MESH_PROP_ID_PRECISE_TOT_DEV_ENERGY_USE) {
		printk("Sensor status from 0x%04x: unhandled property 0x%04x\n",
		       ctx->addr, sensor->id);
		return;
	}

	int64_t micro_kwh = 0;
	enum bt_mesh_sensor_value_status st =
		bt_mesh_sensor_value_to_micro(&value[0], &micro_kwh);
	char msg[64];

	if (!bt_mesh_sensor_value_status_is_numeric(st)) {
		printk("Energy status from 0x%04x: non-numeric value (status %d)\n",
		       ctx->addr, (int)st);
		snprintf(msg, sizeof(msg), "src=0x%04x ukwh=unknown", ctx->addr);
		uart30_send(msg, "Energy_status");
		return;
	}
	printk("Energy status from 0x%04x: %lld micro-kWh\n", ctx->addr, micro_kwh);

	snprintf(msg, sizeof(msg), "src=0x%04x ukwh=%lld", ctx->addr, micro_kwh);

	uart30_send(msg, "Energy_status");
}

static const struct bt_mesh_sensor_cli_handlers sensor_cli_handlers = {
	.data = sensor_data_cb,
};

static struct bt_mesh_sensor_cli sensor_cli =
	BT_MESH_SENSOR_CLI_INIT(&sensor_cli_handlers);

#if defined(CONFIG_BT_MESH_DFD_SRV)
static struct bt_mesh_dfd_srv dfd_srv;
#endif

#if defined(CONFIG_BT_MESH_SAR_CFG_CLI)
static struct bt_mesh_sar_cfg_cli sar_cfg_cli;
#endif

#if defined(CONFIG_BT_MESH_PRIV_BEACON_CLI)
static struct bt_mesh_priv_beacon_cli priv_beacon_cli;
#endif

#if defined(CONFIG_BT_MESH_SOL_PDU_RPL_CLI)
static struct bt_mesh_sol_pdu_rpl_cli srpl_cli;
#endif


#if defined(CONFIG_BT_MESH_OD_PRIV_PROXY_CLI)
static struct bt_mesh_od_priv_proxy_cli od_priv_proxy_cli;
#endif

#if defined(CONFIG_BT_MESH_LARGE_COMP_DATA_CLI)
struct bt_mesh_large_comp_data_cli large_comp_data_cli;
#endif

#if defined(CONFIG_BT_MESH_BRG_CFG_CLI)
static struct bt_mesh_brg_cfg_cli brg_cfg_cli;
#endif

BT_MESH_SHELL_HEALTH_PUB_DEFINE(health_pub);

static const struct bt_mesh_model root_models[] = {
	BT_MESH_MODEL_CFG_SRV,
	BT_MESH_MODEL_CFG_CLI(&cfg_cli),
	BT_MESH_MODEL_ONOFF_CLI(&onoff_cli),
	BT_MESH_MODEL_LIGHTNESS_CLI(&lightness_cli),
	BT_MESH_MODEL_SCENE_CLI(&scene_cli),
	BT_MESH_MODEL_HEALTH_SRV(&bt_mesh_shell_health_srv, &health_pub, health_srv_meta),
	BT_MESH_MODEL_HEALTH_CLI(&bt_mesh_shell_health_cli),
#if defined(CONFIG_BT_MESH_DFD_SRV)
	BT_MESH_MODEL_DFD_SRV(&dfd_srv),
#else
#if defined(CONFIG_BT_MESH_SHELL_DFU_SRV)
	BT_MESH_MODEL_DFU_SRV(&bt_mesh_shell_dfu_srv),
#elif defined(CONFIG_BT_MESH_SHELL_BLOB_SRV)
	BT_MESH_MODEL_BLOB_SRV(&bt_mesh_shell_blob_srv),
#endif
#if defined(CONFIG_BT_MESH_SHELL_DFU_CLI)
	BT_MESH_MODEL_DFU_CLI(&bt_mesh_shell_dfu_cli),
#elif defined(CONFIG_BT_MESH_SHELL_BLOB_CLI)
	BT_MESH_MODEL_BLOB_CLI(&bt_mesh_shell_blob_cli),
#endif
#endif /* CONFIG_BT_MESH_DFD_SRV */
#if defined(CONFIG_BT_MESH_RPR_CLI)
	BT_MESH_MODEL_RPR_CLI(&rpr_cli),
#endif
#if defined(CONFIG_BT_MESH_RPR_SRV)
	BT_MESH_MODEL_RPR_SRV,
#endif

#if defined(CONFIG_BT_MESH_SAR_CFG_SRV)
	BT_MESH_MODEL_SAR_CFG_SRV,
#endif
#if defined(CONFIG_BT_MESH_SAR_CFG_CLI)
	BT_MESH_MODEL_SAR_CFG_CLI(&sar_cfg_cli),
#endif

#if defined(CONFIG_BT_MESH_OP_AGG_SRV)
	BT_MESH_MODEL_OP_AGG_SRV,
#endif
#if defined(CONFIG_BT_MESH_OP_AGG_CLI)
	BT_MESH_MODEL_OP_AGG_CLI,
#endif

#if defined(CONFIG_BT_MESH_LARGE_COMP_DATA_SRV)
	BT_MESH_MODEL_LARGE_COMP_DATA_SRV,
#endif
#if defined(CONFIG_BT_MESH_LARGE_COMP_DATA_CLI)
	BT_MESH_MODEL_LARGE_COMP_DATA_CLI(&large_comp_data_cli),
#endif

#if defined(CONFIG_BT_MESH_PRIV_BEACON_SRV)
	BT_MESH_MODEL_PRIV_BEACON_SRV,
#endif
#if defined(CONFIG_BT_MESH_PRIV_BEACON_CLI)
	BT_MESH_MODEL_PRIV_BEACON_CLI(&priv_beacon_cli),
#endif
#if defined(CONFIG_BT_MESH_OD_PRIV_PROXY_CLI)
	BT_MESH_MODEL_OD_PRIV_PROXY_CLI(&od_priv_proxy_cli),
#endif
#if defined(CONFIG_BT_MESH_SOL_PDU_RPL_CLI)
	BT_MESH_MODEL_SOL_PDU_RPL_CLI(&srpl_cli),
#endif
#if defined(CONFIG_BT_MESH_OD_PRIV_PROXY_SRV)
	BT_MESH_MODEL_OD_PRIV_PROXY_SRV,
#endif
#if defined(CONFIG_BT_MESH_BRG_CFG_SRV)
	BT_MESH_MODEL_BRG_CFG_SRV,
#endif
#if defined(CONFIG_BT_MESH_BRG_CFG_CLI)
	BT_MESH_MODEL_BRG_CFG_CLI(&brg_cfg_cli),
#endif
	/* Appended last on purpose: keeps the composition-data model indices of
	 * every model above unchanged, so a firmware update that adds this model
	 * doesn't misalign bindings/subscriptions restored from flash.
	 */
	BT_MESH_MODEL_SENSOR_CLI(&sensor_cli),
};

static const struct bt_mesh_elem elements[] = {
	BT_MESH_ELEM(0, root_models, BT_MESH_MODEL_NONE),
};


static const struct bt_mesh_comp comp = {
	.cid = CONFIG_BT_COMPANY_ID,
	.elem = elements,
	.elem_count = ARRAY_SIZE(elements),
};

const struct bt_mesh_comp *model_handler_init(void)
{
	return &comp;
}

/* creates and send a mesh message setting the on/off state of a light */
int model_handler_onoff_set(uint16_t net_idx, uint16_t app_idx, uint16_t dst_addr, bool on_off)
{
	struct bt_mesh_msg_ctx ctx = {
		.net_idx = net_idx,
		.app_idx = app_idx,
		.addr = dst_addr,
		.send_ttl = BT_MESH_TTL_DEFAULT,
	};
	struct bt_mesh_onoff_set set = {
		.on_off = on_off,
		.reuse_transaction = false,
		.transition = NULL,
	};

	if (!bt_mesh_is_provisioned()) {
		return -EAGAIN;
	}

	return bt_mesh_onoff_cli_set_unack(&onoff_cli, &ctx, &set);
}

/* sets the absolute brightness (0-100%) of a Light Lightness Server fixture */
int model_handler_lightness_set(uint16_t net_idx, uint16_t app_idx, uint16_t dst_addr,
				uint8_t percent)
{
	if (percent > 100U) {
		percent = 100U;
	}

	struct bt_mesh_msg_ctx ctx = {
		.net_idx = net_idx,
		.app_idx = app_idx,
		.addr = dst_addr,
		.send_ttl = BT_MESH_TTL_DEFAULT,
	};
	struct bt_mesh_lightness_set set = {
		/* Scale 0-100% to the 0-65535 Lightness Actual range. */
		.lvl = (uint16_t)(((uint32_t)percent * 65535U) / 100U),
		.transition = NULL,
	};

	if (!bt_mesh_is_provisioned()) {
		return -EAGAIN;
	}

	return bt_mesh_lightness_cli_light_set_unack(&lightness_cli, &ctx, &set);
}

/* recalls a stored scene on a Scene Server */
int model_handler_scene_recall(uint16_t net_idx, uint16_t app_idx, uint16_t dst_addr,
			       uint16_t scene)
{
	struct bt_mesh_msg_ctx ctx = {
		.net_idx = net_idx,
		.app_idx = app_idx,
		.addr = dst_addr,
		.send_ttl = BT_MESH_TTL_DEFAULT,
	};

	if (!bt_mesh_is_provisioned()) {
		return -EAGAIN;
	}

	return bt_mesh_scene_cli_recall_unack(&scene_cli, &ctx, scene, NULL);
}

/* stores the current fixture state as a scene on a Scene Server */
int model_handler_scene_store(uint16_t net_idx, uint16_t app_idx, uint16_t dst_addr,
			      uint16_t scene)
{
	struct bt_mesh_msg_ctx ctx = {
		.net_idx = net_idx,
		.app_idx = app_idx,
		.addr = dst_addr,
		.send_ttl = BT_MESH_TTL_DEFAULT,
	};

	if (!bt_mesh_is_provisioned()) {
		return -EAGAIN;
	}

	return bt_mesh_scene_cli_store_unack(&scene_cli, &ctx, scene);
}

/* Read Precise Total Device Energy Use from a fixture's Sensor Server.
 * Non-blocking (rsp = NULL): the decoded value arrives in sensor_data_cb.
 */
int model_handler_sensor_get(uint16_t net_idx, uint16_t app_idx, uint16_t dst_addr)
{
	struct bt_mesh_msg_ctx ctx = {
		.net_idx = net_idx,
		.app_idx = app_idx,
		.addr = dst_addr,
		.send_ttl = BT_MESH_TTL_DEFAULT,
	};

	if (!bt_mesh_is_provisioned()) {
		return -EAGAIN;
	}

	return bt_mesh_sensor_cli_get(&sensor_cli, &ctx,
				      &bt_mesh_sensor_precise_tot_dev_energy_use, NULL);
}
```

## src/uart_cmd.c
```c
/*
 * Copyright (c) 2026 Nordic Semiconductor ASA
 *
 * SPDX-License-Identifier: LicenseRef-Nordic-5-Clause
 */

#include "uart_cmd.h"
#include <stdbool.h>
#include <stdint.h>
#include <zephyr/kernel.h>
#include <zephyr/drivers/uart.h>
#include <zephyr/sys/printk.h>
#include <string.h>
#include <stdio.h>
#include "gtw_shell.h"

#define CMD_BUFFER_SIZE 256

static const struct device *uart_dev;

/* mutex to serialize UART TX so multiple threads can send messages without interleaving */
static K_MUTEX_DEFINE(tx_mutex);

/* removes ANSI escape codes and other unwanted characters from the input string */
size_t strip_ansi_escapes(const char *src, size_t src_len, char *dst, size_t dst_size)
{
	size_t dst_pos = 0;
	size_t i = 0;

	while (i < src_len && dst_pos < dst_size - 1) {
		if (src[i] == 0x1b) {
			i++;
			if (i < src_len && src[i] == '[') {
				i++;
				while (i < src_len && ((src[i] < '@' || src[i] > '~'))) {
					i++;
				}
				if (i < src_len) {
					i++;
				}
			}
		} else if (src[i] == '~' && i + 2 < src_len && src[i+1] == '$' && src[i+2] == ' ') {
			i += 3;
		} else if (src[i] == '\r') {
			i++;
		} else {
			dst[dst_pos++] = src[i++];
		}
	}
	dst[dst_pos] = '\0';
	return dst_pos;
}

/* sends string over uart to nRF9151 */
void uart30_send(const char *data, const char *subject)
{
	if (!uart_dev || !device_is_ready(uart_dev)) {
		return;
	}
	static char json_buf[CONFIG_SHELL_BACKEND_DUMMY_BUF_SIZE];

	snprintf(json_buf, sizeof(json_buf), "%s %s", subject, data);
	size_t json_len = strip_ansi_escapes(json_buf, strlen(json_buf), json_buf,
					      sizeof(json_buf));

	/* Lock down the UART send so that multiple threads don't send at the same time */
	k_mutex_lock(&tx_mutex, K_FOREVER);
	for (size_t i = 0; i < json_len; i++) {
		uart_poll_out(uart_dev, json_buf[i]);

		/* for each new line, send the subject first again */
		/* nrf9151 expects the first word of a line to be the subject */
		if (json_buf[i] == '\n') {
			for (int i = 0; i < strlen(subject); i++) {
				uart_poll_out(uart_dev, subject[i]);

			}
			uart_poll_out(uart_dev, ' ');
		}
	}
	uart_poll_out(uart_dev, '\n');
	k_mutex_unlock(&tx_mutex);
}

/* receives uart commands from uart and queues them for execution */
static void uart_isr(const struct device *dev, void *user_data)
{
	ARG_UNUSED(user_data);

	static char uart_buffer[CMD_BUFFER_SIZE];
	static size_t uart_buffer_pos;
	uint8_t c;

	if (!uart_irq_update(dev)) {
		return;
	}
	if (!uart_irq_rx_ready(dev)) {
		return;
	}
	while (uart_fifo_read(dev, &c, 1) == 1) {
		if (c == '\r' || c == '\n') {
			if (uart_buffer_pos > 0) {
				/* queue command and reset buffer */
				queue_shell_cmd(uart_buffer);
				uart_buffer_pos = 0;
				memset(uart_buffer, 0, sizeof(uart_buffer));
			} else {
				printk("Received empty command, ignoring\n");
			}

		} else if (uart_buffer_pos < CMD_BUFFER_SIZE - 1) {
			/* add character to buffer */
			uart_buffer[uart_buffer_pos++] = (char)c;
		} else {
			printk("Command buffer overflow, resetting\n");
			uart_buffer_pos = 0;
			memset(uart_buffer, 0, sizeof(uart_buffer));
		}
	}
}

int uart_cmd_init(void)
{
	int err;

	uart_dev = DEVICE_DT_GET(DT_NODELABEL(uart30));
	if (!device_is_ready(uart_dev)) {
		printk("UART command device not ready\n");
		return -ENODEV;
	}
	err = uart_irq_callback_user_data_set(uart_dev, uart_isr, NULL);
	if (err < 0) {
		if (err == -ENOTSUP) {
			printk("Interrupt-driven UART API not enabled\n");
		}
		return err;
	}
	uart_irq_rx_enable(uart_dev);

	printk("UART command reception initialized on UART30\n");
	printk("TX: P0.0, RX: P0.1, 115200 baud\n");
	return 0;
}
```
